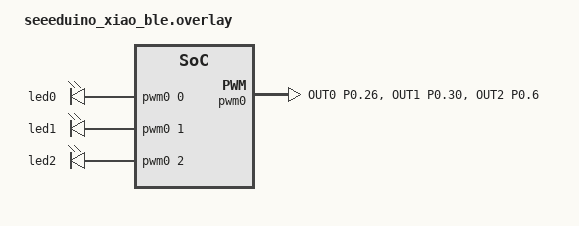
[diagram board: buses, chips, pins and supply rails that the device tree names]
/ {
    aliases {
        led-red = &led0;
        led-green = &led1;
        led-blue = &led2;
    };

    /delete-node/ leds;

    leds {
        compatible = "pwm-leds";
        led0: led_0 {
            pwms = <&pwm0 0 PWM_MSEC(10) PWM_POLARITY_INVERTED>;
        };
        led1: led_1 {
            pwms = <&pwm0 1 PWM_MSEC(10) PWM_POLARITY_INVERTED>;
        };
        led2: led_2 {
            pwms = <&pwm0 2 PWM_MSEC(10) PWM_POLARITY_INVERTED>;
        };
    };
};

&pwm0 {
    status = "okay";
    pinctrl-0 = <&pwm0_default>;
    pinctrl-1 = <&pwm0_sleep>;
    pinctrl-names = "default", "sleep";
};

&pinctrl {
    pwm0_default: pwm0_default {
        group1 {
            psels = <NRF_PSEL(PWM_OUT0, 0, 26)>,
                    <NRF_PSEL(PWM_OUT1, 0, 30)>,
                    <NRF_PSEL(PWM_OUT2, 0,  6)>;
        };
    };
    pwm0_sleep: pwm0_sleep {
        group1 {
            psels = <NRF_PSEL(PWM_OUT0, 0, 26)>,
                    <NRF_PSEL(PWM_OUT1, 0, 30)>,
                    <NRF_PSEL(PWM_OUT2, 0,  6)>;
            low-power-enable;
        };
    };
};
